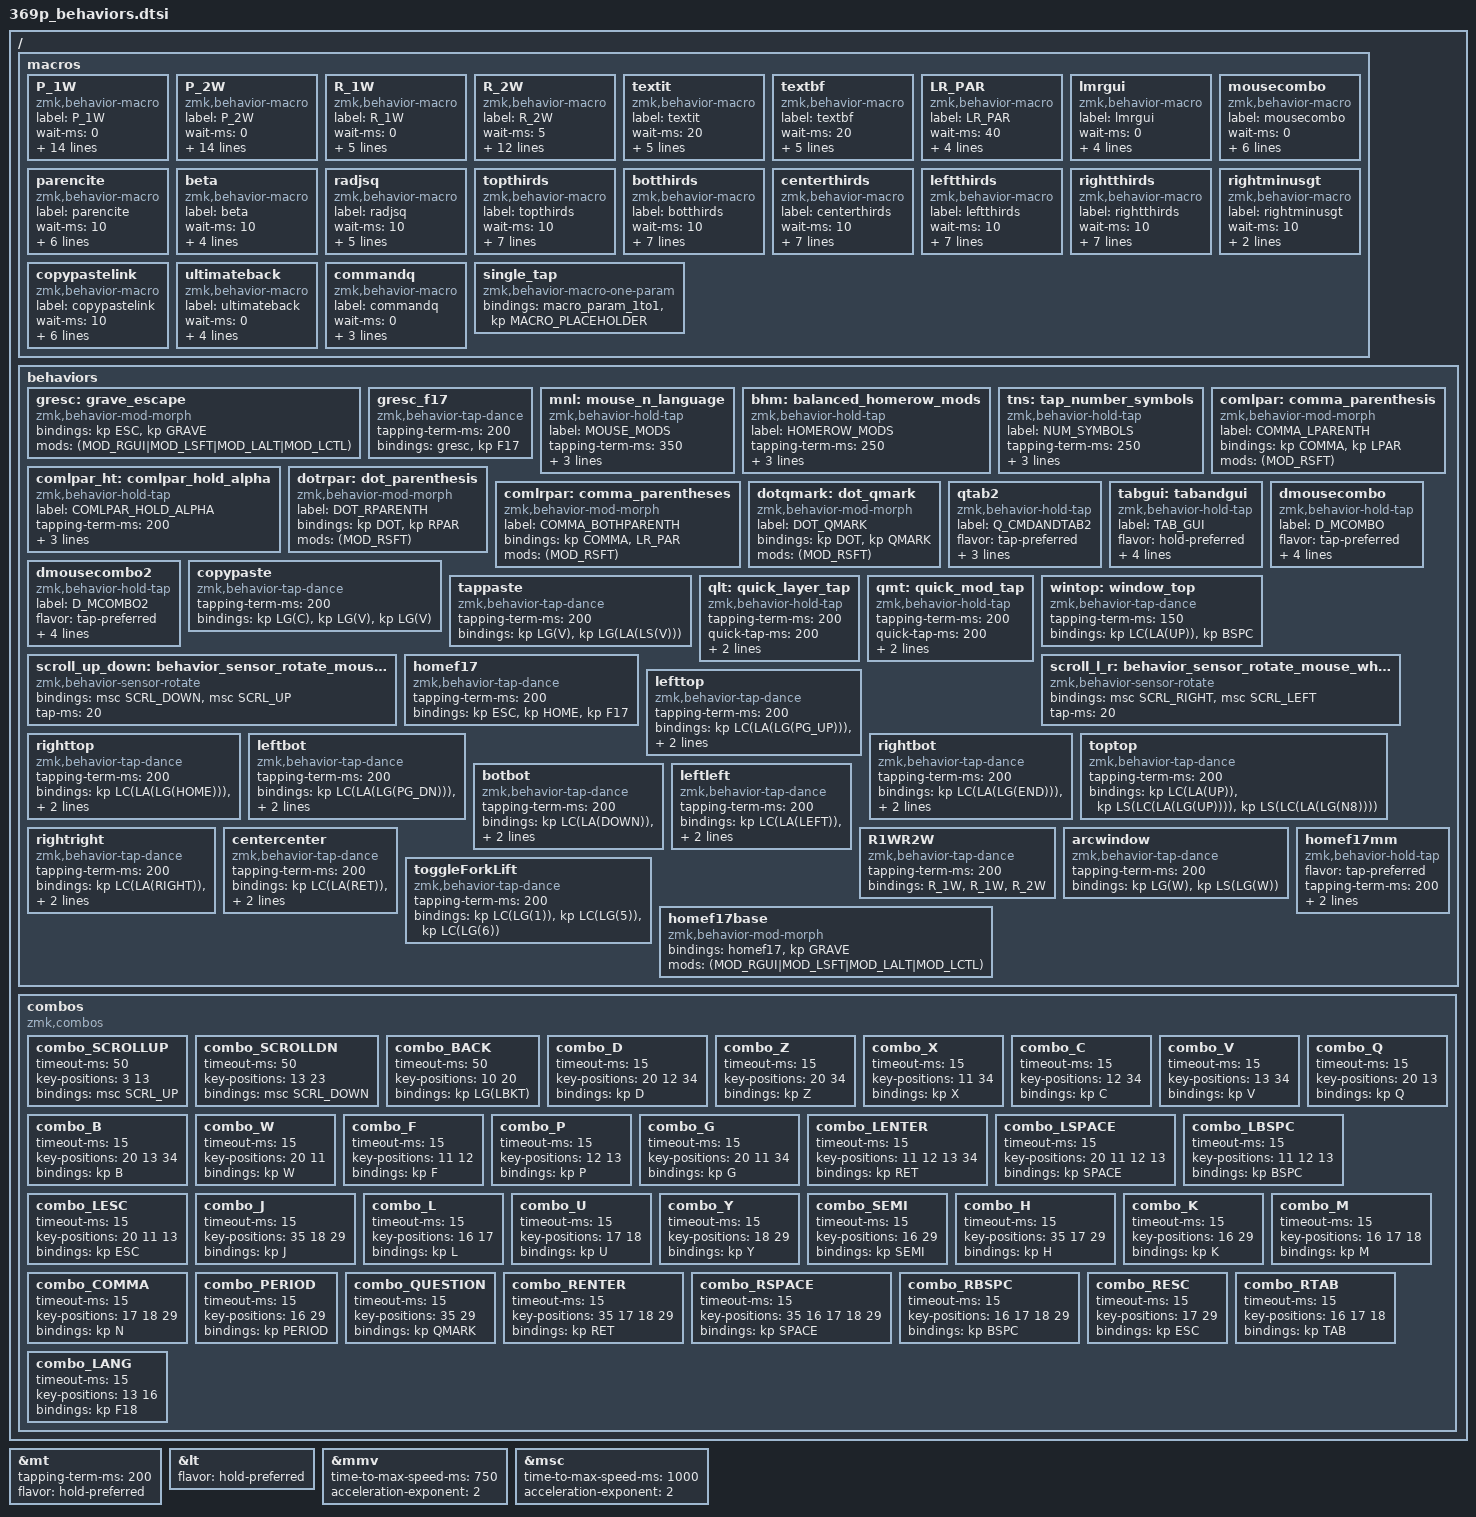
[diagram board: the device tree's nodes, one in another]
/*
 * Copyright (c) 2020 The ZMK Contributors
 *
 * SPDX-License-Identifier: MIT
 *
 * Shared macros, behaviors, and combos for the 369p keymap.
 * Included by 369p.keymap.
 */

#include <behaviors.dtsi>
#include <dt-bindings/zmk/keys.h>
#include <dt-bindings/zmk/bt.h>
#include <dt-bindings/zmk/outputs.h>
// #include <dt-bindings/zmk/mouse.h>        
#include <dt-bindings/zmk/pointing.h>

#define qwerty 0
#define colemnk 1
#define lower 2
#define raise 3
#define adjust 4
#define commandlayer 5
#define extra 6
#define mouse 7
// #define cmtoqw 6
// #define lock 7
// #define locklow 8
// #define unlock 9
// #define lockhigh 10/
#define ZMK_POINTING_DEFAULT_MOVE_VAL 3500  // default: 600
#define ZMK_POINTING_DEFAULT_SCRL_VAL 140

&mt {
    tapping-term-ms = <200>;
    flavor = "hold-preferred";
};

&lt {
   flavor = "hold-preferred";
};

/* Mouse movement: start slow with fine control, then accelerate gradually.
 * acceleration-exponent = 2 → quadratic ramp (slow, granular start that speeds up);
 * larger time-to-max-speed-ms → takes longer to reach full speed (slower acceleration).
 * (defaults were 300 ms / exponent 1.) */
&mmv {
    time-to-max-speed-ms = <750>;
    acceleration-exponent = <2>;
};

/* Mouse scroll up/down/left/right: same feel — fine, slow scrolling at first that
 * accelerates. (defaults were 300 ms / exponent 0, i.e. no acceleration at all.) */
&msc {
    time-to-max-speed-ms = <1000>;
    acceleration-exponent = <2>;
};

/{ // <---[[root node]]    
    macros {
        // |XteZB8Yrdc SBRzu1UX
        P_1W: P_1W {
            label = "P_1W";
            compatible = "zmk,behavior-macro";
            #binding-cells = <0>;
            wait-ms = <0>;
            tap-ms = <0>;
            bindings
                = <&macro_tap &kp PIPE>
                , <&macro_press &kp LSHFT>
                , <&macro_tap &kp X>
                , <&macro_release &kp LSHFT>
                , <&macro_tap &kp T &kp E>
                , <&macro_press &kp LSHFT>
                , <&macro_tap &kp Z &kp B>
                , <&macro_release &kp LSHFT>
                , <&macro_tap &kp N8>
                , <&macro_press &kp LSHFT>
                , <&macro_tap &kp Y>
                , <&macro_release &kp LSHFT>
                , <&macro_tap &kp R &kp D &kp C &kp SPACE>
                , <&macro_press &kp LSHFT>
                , <&macro_tap &kp S &kp B &kp R>
                , <&macro_press &kp LSHFT>
                , <&macro_tap &kp Z &kp U &kp 1>
                , <&macro_press &kp LSHFT>
                , <&macro_tap &kp U &kp X>
                , <&macro_release &kp LSHFT>
                ;
        };
        P_2W: P_2W {
            label = "P_2W";
            compatible = "zmk,behavior-macro";
            #binding-cells = <0>;
            wait-ms = <0>;
            tap-ms = <0>;
            bindings
                = <&macro_tap &kp PIPE>
                , <&macro_press &kp LSHFT>
                , <&macro_tap &kp X>
                , <&macro_release &kp LSHFT>
                , <&macro_tap &kp G &kp F>
                , <&macro_press &kp LSHFT>
                , <&macro_tap &kp Z &kp B>
                , <&macro_release &kp LSHFT>
                , <&macro_tap &kp N8>
                , <&macro_press &kp LSHFT>
                , <&macro_tap &kp J>
                , <&macro_release &kp LSHFT>
                , <&macro_tap &kp P &kp S &kp C &kp SPACE>
                , <&macro_press &kp LSHFT>
                , <&macro_tap &kp R &kp B &kp P>
                , <&macro_press &kp LSHFT>
                , <&macro_tap &kp Z &kp L &kp 1>
                , <&macro_press &kp LSHFT>
                , <&macro_tap &kp L &kp X>
                , <&macro_release &kp LSHFT>
                ;
        };
        R_1W: R_1W {
            label = "R_1W";
            compatible = "zmk,behavior-macro";
            #binding-cells = <0>;
            wait-ms = <0>;
            tap-ms = <0>;
            bindings
                = <&macro_press &kp LSHFT>
                , <&macro_tap &kp S>
                , <&macro_release &kp LSHFT>
                , <&macro_tap &kp H &kp A &kp W &kp U &kp A &kp J &kp Y &kp D &kp S &kp N>
                ;
        };
        R_2W: R_2W {
            label = "R_2W";
            compatible = "zmk,behavior-macro";
            #binding-cells = <0>;
            wait-ms = <5>;
            tap-ms = <10>;
            bindings
                = <&macro_tap &kp PIPE>
                , <&macro_press &kp LSHFT>
                , <&macro_tap &kp X>
                , <&macro_release &kp LSHFT>
                , <&macro_tap &kp T &kp E>
                , <&macro_press &kp LSHFT>
                , <&macro_tap &kp Z &kp B>
                , <&macro_release &kp LSHFT>
                , <&macro_tap &kp N8>
                , <&macro_press &kp LSHFT>
                , <&macro_tap &kp Y>
                , <&macro_release &kp LSHFT>
                , <&macro_tap &kp R &kp D &kp C &kp SPACE>
                , <&macro_press &kp LSHFT>
                , <&macro_tap &kp S &kp B &kp R>
                , <&macro_release &kp LSHFT>
                , <&macro_tap &kp Z &kp U &kp 1>
                ;
        };
        textit: textit {
            label = "textit";
            compatible = "zmk,behavior-macro";
            #binding-cells = <0>;
            wait-ms = <20>;
            tap-ms = <10>;
            bindings
                = <&macro_tap 
                &kp LBRC &kp LEFT &kp LEFT
                &kp BSLH &kp F &kp K &kp X &kp F &kp L &kp F>
                ,<&macro_press &kp LALT>
                ,<&macro_tap &kp RIGHT &kp RIGHT>
                ,<&macro_release &kp LALT>
                ;
        };
        textbf: textbf {
            label = "textbf";
            compatible = "zmk,behavior-macro";
            #binding-cells = <0>;
            wait-ms = <20>;
            tap-ms = <10>;
            bindings
                = <&macro_tap 
                &kp LBRC &kp LEFT &kp LEFT
                &kp BSLH &kp F &kp K &kp X &kp F &kp B &kp E>
                ,<&macro_press 
                &kp LALT>
                ,<&macro_tap 
                &kp RIGHT &kp RIGHT>
                ,<&macro_release 
                &kp LALT>
                ;
        };
        LR_PAR: LR_PAR {
            label = "LR_PAR";
            compatible = "zmk,behavior-macro";
            #binding-cells = <0>;
            wait-ms = <40>;
            tap-ms = <40>;
            bindings
                = <&macro_press &kp LSHFT>
                , <&macro_tap &kp N9 &kp N0>
                , <&macro_release &kp LSHFT>
                , <&macro_tap &kp LEFT>
                ;
        };
        lmrgui: lmrgui {
            label = "lmrgui";
            compatible = "zmk,behavior-macro";
            wait-ms = <0>;
            tap-ms = <0>;
            #binding-cells = <0>;
            bindings
                = <&macro_press &mo commandlayer &kp RGUI>
                , <&macro_pause_for_release>
                , <&macro_release &mo commandlayer &kp RGUI>
                ;
        };
        mousecombo: mousecombo {
            label = "mousecombo";
            compatible = "zmk,behavior-macro";
            wait-ms = <0>;
            tap-ms = <0>;
            #binding-cells = <0>;
            bindings
                = <&macro_press &kp LGUI &kp LSHFT> 
                , <&macro_tap &kp SPACE>
                , <&macro_release &kp LGUI &kp LSHFT>
                , <&macro_press &mo mouse>
                , <&macro_pause_for_release>
                , <&macro_release &mo mouse>
                ;
        };
        parencite: parencite {
            label = "parencite";
            compatible = "zmk,behavior-macro";
            #binding-cells = <0>;
            wait-ms = <10>;
            tap-ms = <20>;
            bindings
                = <&macro_tap &kp BSLH &kp R &kp A &kp S &kp K &kp J &kp C &kp L &kp F &kp K>
                , <&macro_tap &kp LBKT &kp RBKT  &kp LBRC &kp RBRC &kp LEFT &kp LEFT &kp LBKT &kp RBKT &kp RIGHT &kp RIGHT>
                ;
        };
        // \(\beta\)
        beta: beta {
            label = "beta";
            compatible = "zmk,behavior-macro";
            #binding-cells = <0>;
            wait-ms = <10>;
            tap-ms = <30>;
            bindings
                = <&macro_tap &kp BSLH &kp LPAR &kp BSLH &kp B &kp K &kp J &kp A &kp BSLH &kp RPAR>
                ;
        };
        // ($R^2_{adj}$
        radjsq: radjsq {
            label = "radjsq";
            compatible = "zmk,behavior-macro";
            #binding-cells = <0>;
            wait-ms = <10>;
            tap-ms = <30>;
            bindings
                = <&macro_tap &kp LPAR &kp DLLR>
                , <&macro_press &kp RSHFT> 
                , <&kp S>
                , <&macro_release &kp RSHFT>
                , <&kp AMPS &kp UNDER &kp LBRC &kp A &kp G &kp Y &kp RBRC &kp DLLR>
                ;
        };
        topthirds: topthirds {
            label = "topthirds";
            compatible = "zmk,behavior-macro";
            #binding-cells = <0>;
            wait-ms = <10>;
            tap-ms = <30>;
            bindings
                = <&macro_press &kp LSHFT>
                , <&macro_press &kp LCTL>
                , <&macro_press &kp LALT>
                , <&macro_press &kp LGUI>
                , <&macro_tap &kp N8 &kp F4>
                , <&macro_release &kp LSHFT>
                , <&macro_release &kp LCTL>
                , <&macro_release &kp LALT>
                , <&macro_release &kp LGUI>
                ;
        };
        botthirds: botthirds {
            label = "botthirds";
            compatible = "zmk,behavior-macro";
            #binding-cells = <0>;
            wait-ms = <10>;
            tap-ms = <30>;
            bindings
                = <&macro_press &kp LSHFT>
                , <&macro_press &kp LCTL>
                , <&macro_press &kp LALT>
                , <&macro_press &kp LGUI>
                , <&macro_tap &kp N5 &kp F6>
                , <&macro_release &kp LSHFT>
                , <&macro_release &kp LCTL>
                , <&macro_release &kp LALT>
                , <&macro_release &kp LGUI>
                ;
        };
        centerthirds: centerthirds {
            label = "centerthirds";
            compatible = "zmk,behavior-macro";
            #binding-cells = <0>;
            wait-ms = <10>;
            tap-ms = <30>;
            bindings
                = <&macro_press &kp LSHFT>
                , <&macro_press &kp LCTL>
                , <&macro_press &kp LALT>
                , <&macro_press &kp LGUI>
                , <&macro_tap &kp N2 &kp F5>
                , <&macro_release &kp LSHFT>
                , <&macro_release &kp LCTL>
                , <&macro_release &kp LALT>
                , <&macro_release &kp LGUI>
                ;
        };
        leftthirds: leftthirds {
            label = "leftthirds";
            compatible = "zmk,behavior-macro";
            #binding-cells = <0>;
            wait-ms = <10>;
            tap-ms = <30>;
            bindings
                = <&macro_press &kp LSHFT>
                , <&macro_press &kp LCTL>
                , <&macro_press &kp LALT>
                , <&macro_press &kp LGUI>
                , <&macro_tap &kp N1 &kp M>
                , <&macro_release &kp LSHFT>
                , <&macro_release &kp LCTL>
                , <&macro_release &kp LALT>
                , <&macro_release &kp LGUI>
                ;
        };
        rightthirds: rightthirds {
            label = "rightthirds";
            compatible = "zmk,behavior-macro";
            #binding-cells = <0>;
            wait-ms = <10>;
            tap-ms = <30>;
            bindings
                = <&macro_press &kp LSHFT>
                , <&macro_press &kp LCTL>
                , <&macro_press &kp LALT>
                , <&macro_press &kp LGUI>
                , <&macro_tap &kp N3 &kp M>
                , <&macro_release &kp LSHFT>
                , <&macro_release &kp LCTL>
                , <&macro_release &kp LALT>
                , <&macro_release &kp LGUI>
                ;
        };
        rightminusgt: rightminusgt {
            label = "rightminusgt";
            compatible = "zmk,behavior-macro";
            #binding-cells = <0>;
            wait-ms = <10>;
            tap-ms = <30>;
            bindings
                = <&macro_tap &kp MINUS &kp GT>
                ;
        };
        copypastelink: copypastelink {
            label = "copypastelink";
            compatible = "zmk,behavior-macro";
            #binding-cells = <0>;
            wait-ms = <10>;
            tap-ms = <30>;
            bindings
                = <&macro_press &kp LGUI>
                , <&macro_tap &kp U &kp C &kp TAB>
                , <&macro_release &kp LGUI>
                , <&macro_press &kp LGUI>
                , <&macro_tap &kp F>
                , <&macro_wait_time 50>
                , <&macro_tap &kp V>
                , <&macro_release &kp LGUI>
                , <&macro_tap &kp RET>
                ;
        };
        ultimateback: ultimateback {
            label = "ultimateback";
            compatible = "zmk,behavior-macro";
            #binding-cells = <0>;
            wait-ms = <0>;
            tap-ms = <30>;
            bindings
                = <&macro_press &kp LGUI>
                , <&macro_tap &kp LBKT>
                , <&macro_release &kp LGUI>
                , <&macro_tap &kp K_BACK>
                ;
        };
        commandq: commandq {
            label = "commandq";
            compatible = "zmk,behavior-macro";
            #binding-cells = <0>;
            wait-ms = <0>;
            tap-ms = <30>;
            bindings
                = <&macro_press &kp LGUI>
                , <&macro_tap &kp Q>
                , <&macro_release &kp LGUI>
                ;
        };
        single_tap: single_tap {
            compatible = "zmk,behavior-macro-one-param";
            #binding-cells = <1>;
            bindings = <&macro_param_1to1>, <&kp MACRO_PLACEHOLDER>;
        };
    };
    behaviors {
        gresc: grave_escape {
            compatible = "zmk,behavior-mod-morph";
            #binding-cells = <0>;
            bindings = <&kp ESC>, <&kp GRAVE>;
            mods = <(MOD_RGUI|MOD_LSFT|MOD_LALT|MOD_LCTL)>;
        };
        gresc_f17: gresc_f17 {
            compatible = "zmk,behavior-tap-dance";
            #binding-cells = <0>;
            tapping-term-ms = <200>;
            bindings = <&gresc>, <&kp F17>;
        };
        mnl: mouse_n_language {
            compatible = "zmk,behavior-hold-tap";
            label = "MOUSE_MODS";
            #binding-cells = <2>;
            tapping-term-ms = <350>;
            quick-tap-ms = <0>;
            flavor = "tap-preferred";
            bindings = <&mo>, <&kp>;
        };
        bhm: balanced_homerow_mods {
            compatible = "zmk,behavior-hold-tap";
            label = "HOMEROW_MODS";
            #binding-cells = <2>;
            tapping-term-ms = <250>;    // <---[[moderate duration]]
            quick-tap-ms = <0>;
            flavor = "balanced";
            bindings = <&kp>, <&kp>;
        };
        tns: tap_number_symbols {
            compatible = "zmk,behavior-hold-tap";
            label = "NUM_SYMBOLS";
            #binding-cells = <2>;
            tapping-term-ms = <250>;    // <---[[moderate duration]]
            quick-tap-ms = <0>;
            flavor = "tap-preferred";
            bindings = <&single_tap>, <&kp>;
        };//the following two go together
        comlpar: comma_parenthesis {
            compatible = "zmk,behavior-mod-morph";
            label = "COMMA_LPARENTH";
            #binding-cells = <0>;
            bindings = <&kp COMMA>, <&kp LPAR>;
            mods = <(MOD_RSFT)>;
        };
        /* Hold-tap wrapper for comlpar: tap = comma/LPAR morph; hold = a single
         * tap of the alphanumeric key passed as the first parameter (via single_tap,
         * so it fires once with no auto-repeat). The second parameter feeds the tap
         * side (comlpar ignores it), so pass 0.
         * Keymap usage:  &comlpar_ht <ALPHA> 0     e.g.  &comlpar_ht M 0 */
        comlpar_ht: comlpar_hold_alpha {
            compatible = "zmk,behavior-hold-tap";
            label = "COMLPAR_HOLD_ALPHA";
            #binding-cells = <2>;
            tapping-term-ms = <200>;
            quick-tap-ms = <0>;
            flavor = "tap-preferred";
            bindings = <&single_tap>, <&comlpar>;
        };
        dotrpar: dot_parenthesis {
            compatible = "zmk,behavior-mod-morph";
            label = "DOT_RPARENTH";
            #binding-cells = <0>;
            bindings = <&kp DOT>, <&kp RPAR>;
            mods = <(MOD_RSFT)>;
        };//the following two go together        
        comlrpar: comma_parentheses {
            compatible = "zmk,behavior-mod-morph";
            label = "COMMA_BOTHPARENTH";
            #binding-cells = <0>;
            bindings = <&kp COMMA>, <&LR_PAR>;
            mods = <(MOD_RSFT)>;
        };
        dotqmark: dot_qmark {
            compatible = "zmk,behavior-mod-morph";
            label = "DOT_QMARK";
            #binding-cells = <0>;
            bindings = <&kp DOT>, <&kp QMARK>;
            mods = <(MOD_RSFT)>;
        };
        // qtab: q_cmdandtab {
        //     compatible = "zmk,behavior-mod-morph";
        //     label = "Q_CMDANDTAB";
        //     #binding-cells = <0>;
        //     bindings = <&kp Q>, <&kp LG(TAB)>;
        //     mods = <(MOD_LGUI)>;
        // };
        qtab2: qtab2 {
            compatible = "zmk,behavior-hold-tap";
            label = "Q_CMDANDTAB2";
            #binding-cells = <2>;
            flavor = "tap-preferred";
            tapping-term-ms = <250>;
            global-quick-tap;
            bindings = <&commandq>, <&kp>;
        };
        tabgui: tabandgui {
            compatible = "zmk,behavior-hold-tap";
            label = "TAB_GUI";
            #binding-cells = <2>;
            flavor = "hold-preferred";
            tapping-term-ms = <200>;
            quick-tap-ms = <125>;
            global-quick-tap;
            bindings = <&lmrgui>, <&kp>;
        };
        dmousecombo: dmousecombo {
            compatible = "zmk,behavior-hold-tap";
            label = "D_MCOMBO";
            #binding-cells = <2>;
            flavor = "tap-preferred";
            tapping-term-ms = <200>;
            quick-tap-ms = <125>;
            global-quick-tap;
            bindings = <&mousecombo>, <&kp>;
        };
        dmousecombo2: dmousecombo2 {
            compatible = "zmk,behavior-hold-tap";
            label = "D_MCOMBO2";
            #binding-cells = <2>;
            flavor = "tap-preferred";
            tapping-term-ms = <200>;
            quick-tap-ms = <125>;
            global-quick-tap;
            bindings = <&mousecombo>, <&mkp>;
        };
        copypaste: copypaste {
            compatible = "zmk,behavior-tap-dance";
            #binding-cells = <0>;
            tapping-term-ms = <200>;
            bindings = <&kp LG(C)>, <&kp LG(V)>, <&kp LG(V)>;
        };
        tappaste: tappaste {
            compatible = "zmk,behavior-tap-dance";
            #binding-cells = <0>;
            tapping-term-ms = <200>;
            bindings = <&kp LG(V)>, <&kp LG(LA(LS(V)))>;
        };
        // td_mt_bspc: tap_dance_layer_tap {
        //     compatible = "zmk,behavior-tap-dance";
        //     #binding-cells = <0>;
        //     tapping-term-ms = <150>;
        //     bindings = <&lt lower BSPC>, <&kp BSPC>;
        // };
        // td_mtt_spc: tap_dance_layer_tap {
        //     compatible = "zmk,behavior-tap-dance";
        //     #binding-cells = <0>;
        //     tapping-term-ms = <150>;
        //     bindings = <&mt LSHFT SPACE>, <&kp SPACE>;
        // };
        qlt: quick_layer_tap {
            compatible = "zmk,behavior-hold-tap";
            #binding-cells = <2>;
            tapping-term-ms = <200>;
            quick-tap-ms = <200>;
            flavor = "hold-preferred";
            bindings = <&mo>, <&kp>;
        };
        qmt: quick_mod_tap {
            compatible = "zmk,behavior-hold-tap";
            #binding-cells = <2>;
            tapping-term-ms = <200>;
            quick-tap-ms = <200>;
            flavor = "hold-preferred";
            bindings = <&kp>, <&kp>;
        };
        wintop: window_top {
            compatible = "zmk,behavior-tap-dance";
            #binding-cells = <0>;
            tapping-term-ms = <150>;
            bindings = <&kp LC(LA(UP))>, <&kp BSPC>;
        };
        scroll_up_down: behavior_sensor_rotate_mouse_wheel_up_down {
	        compatible = "zmk,behavior-sensor-rotate";
	        #sensor-binding-cells = <0>;
            bindings = <&msc SCRL_DOWN>, <&msc SCRL_UP>;
            tap-ms = <20>;
        };
        scroll_l_r: behavior_sensor_rotate_mouse_wheel_left_right {
	        compatible = "zmk,behavior-sensor-rotate";
	        #sensor-binding-cells = <0>;
            bindings = <&msc SCRL_RIGHT>, <&msc SCRL_LEFT>;
            tap-ms = <20>;
        };
        homef17: homef17 {
            compatible = "zmk,behavior-tap-dance";
            #binding-cells = <0>;
            tapping-term-ms = <200>;
            bindings = <&kp ESC>, <&kp HOME>, <&kp F17>;
        };
        lefttop: lefttop {
            compatible = "zmk,behavior-tap-dance";
            #binding-cells = <0>;
            tapping-term-ms = <200>;
            bindings = <&kp LC(LA(LG(PG_UP)))>, <&kp LS(LC(LA(LG(PIPE))))>, <&kp LS(LC(LA(LG(N7))))>;
        };
        righttop: righttop {
            compatible = "zmk,behavior-tap-dance";
            #binding-cells = <0>;
            tapping-term-ms = <200>;
            bindings = <&kp LC(LA(LG(HOME)))>, <&kp LS(LC(LA(LG(GRAVE))))>, <&kp LS(LC(LA(LG(N9))))>;
        };
        leftbot: leftbot {
            compatible = "zmk,behavior-tap-dance";
            #binding-cells = <0>;
            tapping-term-ms = <200>;
            bindings = <&kp LC(LA(LG(PG_DN)))>, <&kp LS(LC(LA(LG(LEFT))))>, <&kp LS(LC(LA(LG(N4))))>;
        };
        rightbot: rightbot {
            compatible = "zmk,behavior-tap-dance";
            #binding-cells = <0>;
            tapping-term-ms = <200>;
            bindings = <&kp LC(LA(LG(END)))>, <&kp LS(LC(LA(LG(RIGHT))))>, <&kp LS(LC(LA(LG(N6))))>;
        };
        toptop: toptop {
            compatible = "zmk,behavior-tap-dance";
            #binding-cells = <0>;
            tapping-term-ms = <200>;
            bindings = <&kp LC(LA(UP))>, <&kp LS(LC(LA(LG(UP))))>, <&kp LS(LC(LA(LG(N8))))>;
        };
        botbot: botbot {
            compatible = "zmk,behavior-tap-dance";
            #binding-cells = <0>;
            tapping-term-ms = <200>;
            bindings = <&kp LC(LA(DOWN))>, <&kp LS(LC(LA(LG(DOWN))))>, <&kp LS(LC(LA(LG(N2))))>;
        };
        leftleft: leftleft {
            compatible = "zmk,behavior-tap-dance";
            #binding-cells = <0>;
            tapping-term-ms = <200>;
            bindings = <&kp LC(LA(LEFT))>, <&kp LS(LC(LA(LG(LBRC))))>, <&kp LS(LC(LA(LG(N1))))>;
        };
        rightright: rightright {
            compatible = "zmk,behavior-tap-dance";
            #binding-cells = <0>;
            tapping-term-ms = <200>;
            bindings = <&kp LC(LA(RIGHT))>, <&kp LS(LC(LA(LG(RBRC))))>, <&kp LS(LC(LA(LG(N3))))>;
        };
        centercenter: centercenter {
            compatible = "zmk,behavior-tap-dance";
            #binding-cells = <0>;
            tapping-term-ms = <200>;
            bindings = <&kp LC(LA(RET))>, <&kp LS(LC(LA(LG(SQT))))>, <&kp LS(LC(LA(LG(N5))))>;
        };
        R1WR2W: R1WR2W {
            compatible = "zmk,behavior-tap-dance";
            #binding-cells = <0>;
            tapping-term-ms = <200>;
            bindings = <&R_1W>, <&R_1W>, <&R_2W>;
        };
        arcwindow: arcwindow {
            compatible = "zmk,behavior-tap-dance";
            #binding-cells = <0>;
            tapping-term-ms = <200>;
            bindings = <&kp LG(W)>, <&kp LS(LG(W))>;
        };
        toggleForkLift: toggleForkLift {
            compatible = "zmk,behavior-tap-dance";
            #binding-cells = <0>;
            tapping-term-ms = <200>;
            bindings = <&kp LC(LG(1))>, <&kp LC(LG(5))>, <&kp LC(LG(6))>;//name, modified, size
        };
        homef17base: homef17base {
            compatible = "zmk,behavior-mod-morph";
            #binding-cells = <0>;
            bindings = <&homef17>, <&kp GRAVE>;
            mods = <(MOD_RGUI|MOD_LSFT|MOD_LALT|MOD_LCTL)>;
        };
        homef17mm: homef17mm {
            compatible = "zmk,behavior-hold-tap";
            #binding-cells = <2>;
            flavor = "tap-preferred";
            tapping-term-ms = <200>;
            quick-tap-ms = <125>;
            bindings = <&mousecombo>, <&homef17base>;
        
        };
    };
    combos {
        compatible = "zmk,combos";
        combo_SCROLLUP {
            timeout-ms = <50>;
            key-positions = <3 13>;
            bindings = <&msc SCRL_UP>;
        };
        combo_SCROLLDN {
            timeout-ms = <50>;
            key-positions = <13 23>;
            bindings = <&msc SCRL_DOWN>;
        };
        combo_BACK {
            timeout-ms = <50>;
            key-positions = <10 20>;
            bindings = <&kp LG(LBKT)>;
        };
        combo_D {
            timeout-ms = <15>;
            key-positions = <20 12 34>;
            bindings = <&kp D>;
        };
        combo_Z {
            timeout-ms = <15>;
            key-positions = <20 34>;
            bindings = <&kp Z>;
        };
        combo_X {
            timeout-ms = <15>;
            key-positions = <11 34>;
            bindings = <&kp X>;
        };
        combo_C {
            timeout-ms = <15>;
            key-positions = <12 34>;
            bindings = <&kp C>;
        };
        combo_V {
            timeout-ms = <15>;
            key-positions = <13 34>;
            bindings = <&kp V>;
        };
        combo_B {
            timeout-ms = <15>;
            key-positions = <20 13 34>;
            bindings = <&kp B>;
        };
        combo_Q {
            timeout-ms = <15>;
            key-positions = <20 13>;
            bindings = <&kp Q>;
        };
        combo_W {
            timeout-ms = <15>;
            key-positions = <20 11>;
            bindings = <&kp W>;
        };
        combo_F {
            timeout-ms = <15>;
            key-positions = <11 12>;
            bindings = <&kp F>;
        };
        combo_P {
            timeout-ms = <15>;
            key-positions = <12 13>;
            bindings = <&kp P>;
        };
        combo_G {
            timeout-ms = <15>;
            key-positions = <20 11 34>;
            bindings = <&kp G>;
        };
        combo_LENTER {
            timeout-ms = <15>;
            key-positions = <11 12 13 34>;
            bindings = <&kp RET>;
        };
        combo_LSPACE {
            timeout-ms = <15>;
            key-positions = <20 11 12 13>;
            bindings = <&kp SPACE>;
        };
        combo_LBSPC {
            timeout-ms = <15>;
            key-positions = <11 12 13>;
            bindings = <&kp BSPC>;
        };
        combo_LESC {
            timeout-ms = <15>;
            key-positions = <20 11 13>;
            bindings = <&kp ESC>;
        };
        // righthand 35 16 17 18 29
        combo_J {
            timeout-ms = <15>;
            key-positions = <35 18 29>;
            bindings = <&kp J>;
        };
        combo_L {
            timeout-ms = <15>;
            key-positions = <16 17>;
            bindings = <&kp L>;
        };
        combo_U {
            timeout-ms = <15>;
            key-positions = <17 18>;
            bindings = <&kp U>;
        };
        combo_Y {
            timeout-ms = <15>;
            key-positions = <18 29>;
            bindings = <&kp Y>;
        };
        combo_SEMI {
            timeout-ms = <15>;
            key-positions = <16 29>;
            bindings = <&kp SEMI>;
        };
        combo_H {
            timeout-ms = <15>;
            key-positions = <35 17 29>;
            bindings = <&kp H>;
        };
        combo_K {
            timeout-ms = <15>;
            key-positions = <16 29>;
            bindings = <&kp K>;
        };
        combo_M {
            timeout-ms = <15>;
            key-positions = <16 17 18>;
            bindings = <&kp M>;
        };
        combo_COMMA{
            timeout-ms = <15>;
            key-positions = <17 18 29>;
            bindings = <&kp N>;
        };
        combo_PERIOD {
            timeout-ms = <15>;
            key-positions = <16 29>;
            bindings = <&kp PERIOD>;
        };
        combo_QUESTION {
            timeout-ms = <15>;
            key-positions = <35 29>;
            bindings = <&kp QMARK>;
        };
        combo_RENTER {
            timeout-ms = <15>;
            key-positions = <35 17 18 29>;
            bindings = <&kp RET>;
        };
        combo_RSPACE {
            timeout-ms = <15>;
            key-positions = <35 16 17 18 29>;
            bindings = <&kp SPACE>;
        };
        combo_RBSPC {
            timeout-ms = <15>;
            key-positions = <16 17 18 29>;
            bindings = <&kp BSPC>;
        };
        combo_RESC {
            timeout-ms = <15>;
            key-positions = <17 29>;
            bindings = <&kp ESC>;
        };
        combo_RTAB {
            timeout-ms = <15>;
            key-positions = <16 17 18>;
            bindings = <&kp TAB>;
        };
        combo_LANG {
            timeout-ms = <15>;
            key-positions = <13 16>;
            bindings = <&kp F18>;
        };
    };
};
